# ADuCM4050 register map
Vendor: Analog Devices; Series: ADuCM4050; File version: 1p0
CPU: CM4 r0p1, little endian, MPU, FPU, 3 interrupt priority bits
Registers are 32-bit, read-write, reset 0x0 unless marked. A register's access mark holds for its fields unless they carry their own. Offsets are from the block's base; [hi:lo] are bit positions; 'fields as' and 'values as' point back to an identical list.

## TMR0 — General Purpose Timer
Base 0x40000000
Same registers: TMR1 0x40000400, TMR2 0x40000800
0x00 LOAD 16-bit — 16-bit Load Value
  [15:0] VALUE range 0x00000000..0x0000FFFF — Load Value
0x04 CURCNT 16-bit — 16-bit Timer Value
  [15:0] VALUE ro — Current Count
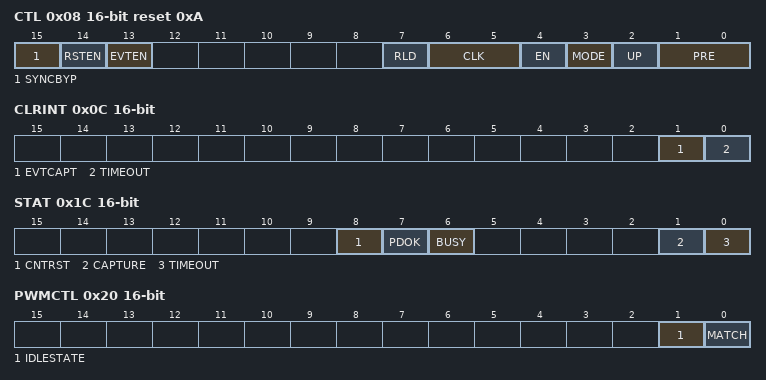
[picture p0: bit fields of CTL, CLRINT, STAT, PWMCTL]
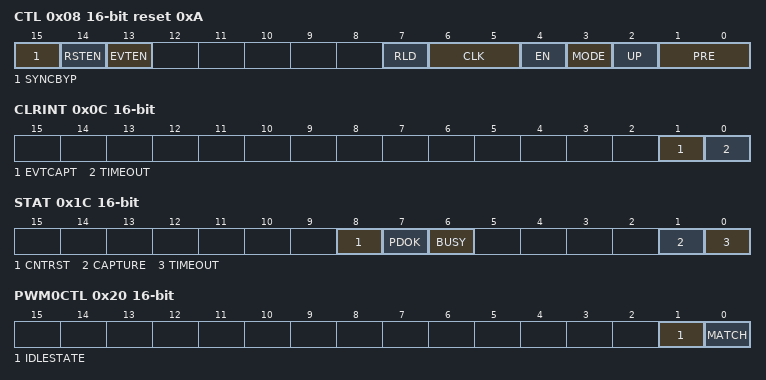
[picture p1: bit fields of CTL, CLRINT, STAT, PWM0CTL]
0x08 CTL 16-bit reset 0xA — Control
  [15] SYNCBYP — Synchronization Bypass
  [14] RSTEN range 0x00000000..0x00000001 — Counter and Prescale Reset Enable
  [13] EVTEN — Event Select
  [7] RLD — Reload Control
  [6:5] CLK — Clock Select
  [4] EN — Timer Enable
  [3] MODE — Timer Mode
  [2] UP — Count up
  [1:0] PRE — Prescaler
0x0C CLRINT 16-bit — Clear Interrupt
  [1] EVTCAPT wo — Clear Captured Event Interrupt
  [0] TIMEOUT wo — Clear Timeout Interrupt
0x10 CAPTURE 16-bit
  [15:0] VALUE ro — 16-bit Captured Value
0x14 ALOAD 16-bit — 16-bit Load Value, Asynchronous
  [15:0] VALUE range 0x00000000..0x0000FFFF — Load Value, Asynchronous
0x18 ACURCNT 16-bit — 16-bit Timer Value, Asynchronous
  [15:0] VALUE ro — Counter Value
0x1C STAT 16-bit — Status
  [8] CNTRST ro — Counter Reset Occurring
  [7] PDOK ro — Clear Interrupt Register Synchronization
  [6] BUSY ro — Timer Busy
  [1] CAPTURE ro — Capture Event Pending
  [0] TIMEOUT ro — Timeout Event Occurred
0x20 PWMCTL 16-bit — PWM Control Register
  [1] IDLESTATE — PWM Idle State
    0=IDLE_LOW (PWM idles low); 1=IDLE_HIGH (PWM idles high)
  [0] MATCH — PWM Match Enabled
    0=PWM_TOGGLE (PWM in toggle mode); 1=PWM_MATCH (PWM in match mode)
0x24 PWMMATCH 16-bit — PWM Match Value
  [15:0] VALUE range 0x00000000..0x0000FFFF
0x28 EVENTSELECT 16-bit — Timer Event Selection Register
  [5:0] EVTRANGE range 0x00000000..0x0000003F — Event Select Range

## TMR_RGB — Timer_RGB with 3 PWM outputs
Base 0x40000C00
0x00 LOAD 16-bit — 16-bit load value
  [15:0] VALUE range 0x00000000..0x0000FFFF — Load value
0x04 CURCNT 16-bit — 16-bit timer value
  [15:0] VALUE ro — Current count
0x08 CTL 16-bit reset 0xA — Control
  [15] SYNCBYP range 0x00000000..0x00000001 — Synchronization bypass
  [14] RSTEN range 0x00000000..0x00000001 — Counter and prescale reset enable
  [13] EVTEN — Event select
  [7] RLD — Reload control
  [6:5] CLK — Clock select
  [4] EN — Timer enable
  [3] MODE — Timer mode
  [2] UP — Count up
  [1:0] PRE — Prescaler
0x0C CLRINT 16-bit — Clear interrupt
  [1] EVTCAPT wo — Clear captured event interrupt
  [0] TIMEOUT wo — Clear timeout interrupt
0x10 CAPTURE 16-bit
  [15:0] VALUE ro — 16-bit captured value
0x14 ALOAD 16-bit — 16-bit load value, asynchronous
  [15:0] VALUE range 0x00000000..0x0000FFFF — Load value, asynchronous
0x18 ACURCNT 16-bit — 16-bit timer value, asynchronous
  [15:0] VALUE ro — Counter value
0x1C STAT 16-bit — Status
  [8] CNTRST ro — Counter reset occurring
  [7] PDOK ro — Clear Interrupt Register synchronization
  [6] BUSY ro — Timer Busy
  [1] CAPTURE ro — Capture event pending
  [0] TIMEOUT ro — Timeout event occurred
0x20 PWM0CTL 16-bit — PWM0 Control Register
  [1] IDLESTATE range 0x00000000..0x00000001 — PWM Idle State
  [0] MATCH range 0x00000000..0x00000001 — PWM Match enabled
0x24 PWM0MATCH 16-bit — PWM0 Match Value
  [15:0] VALUE range 0x00000000..0x0000FFFF — PWM Match Value
0x28 EVENTSELECT 16-bit — Timer Event selection Register
  [5:0] EVTRANGE range 0x00000000..0x0000003F — Event select range
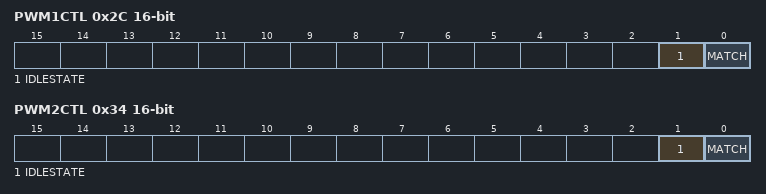
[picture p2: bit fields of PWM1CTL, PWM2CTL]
0x2C PWM1CTL 16-bit — PWM1 Control Register
  fields as PWM0CTL
0x30 PWM1MATCH 16-bit — PWM1 Match Value
  [15:0] VALUE range 0x00000000..0x0000FFFF — PWM Match Value
0x34 PWM2CTL 16-bit — PWM2 Control Register
  fields as PWM0CTL
0x38 PWM2MATCH 16-bit — PWM2 Match Value
  [15:0] VALUE range 0x00000000..0x0000FFFF — PWM Match Value
